# STM32C092 register map
File version: 1.0
CPU: CM0+ r0p0, little endian, MPU, no FPU, 4 interrupt priority bits
Registers are 32-bit, read-write, reset 0x0 unless marked. A register's access mark holds for its fields unless they carry their own. Offsets are from the block's base; [hi:lo] are bit positions; {n}, {i} and the like mark numbered series.

## GPIOA — GPIOA address block description
Base 0x50000000
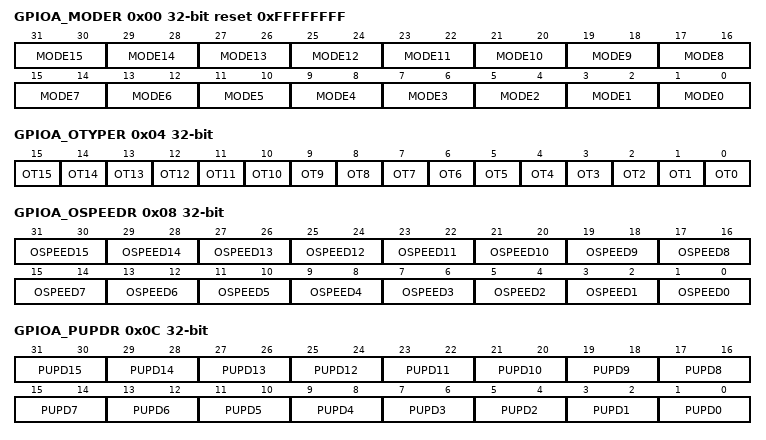
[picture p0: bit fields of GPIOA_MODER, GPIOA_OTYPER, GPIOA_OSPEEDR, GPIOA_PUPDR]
0x00 GPIOA_MODER reset 0xFFFFFFFF — GPIO port mode register
  [all] fields
    0=Input; 1=Output; 2=Alternate function; 3=Analog
  [2n+1:2n] MODE{n} (n=0..15) — Port x configuration for I/O y These bits are written by software to set the I/O to one of four operating modes.
0x04 GPIOA_OTYPER — GPIO port output type register
  [all] fields
    0=Output push-pull (reset state); 1=Output open-drain
  [n] OT{n} (n=0..15) — Port x configuration for I/O y These bits are written by software to configure the I/O output type.
0x08 GPIOA_OSPEEDR — GPIO port output speed register
  [all] fields
    0=Very low speed; 1=Low speed; 2=High speed; 3=Very high speed
  [2n+1:2n] OSPEED{n} (n=0..15) — Port x configuration for I/O y These bits are written by software to configure the I/O output speed. Refer to the device datasheet for the frequency specifications and the power supply and load conditions for each speed.. Note: The FT_c GPIOs cannot be set to high speed.
0x0C GPIOA_PUPDR — GPIO port pull-up/pull-down register
  [all] fields
    0=No pull-up, pull-down; 1=Pull-up; 2=Pull-down
  [2n+1:2n] PUPD{n} (n=0..15) — Port x configuration I/O y These bits are written by software to configure the I/O pull-up or pull-down Note: On the same pin, this pull up/down must not be activated when a pull down/up is set through the PWR_PDCRx/PWR_PUCRx registers.
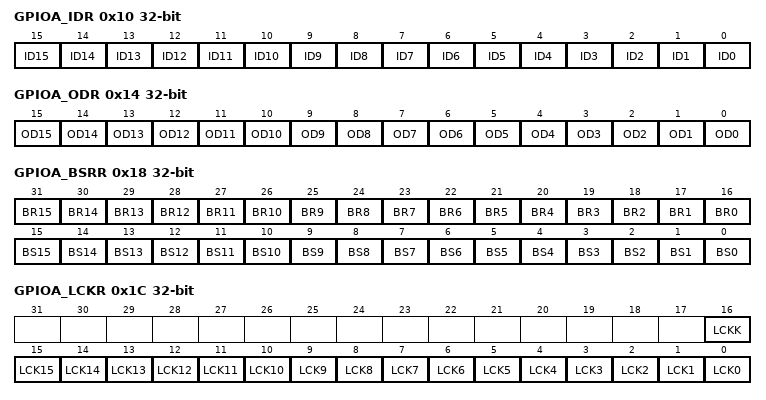
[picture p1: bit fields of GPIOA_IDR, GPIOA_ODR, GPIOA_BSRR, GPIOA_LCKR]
0x10 GPIOA_IDR ro (reset mask 0xFFFF0000) — GPIO port input data register
  [n] ID{n} (n=0..15) — Port x input data I/O y These bits are read-only. They contain the input value of the corresponding I/O port.
0x14 GPIOA_ODR — GPIO port output data register
  [n] OD{n} (n=0..15) — Port output data I/O y These bits can be read and written by software. Note: For atomic bit set/reset, the OD bits can be individually set and/or reset by writing to the GPIOx_BSRR register (x = A, B, C, D, F).
0x18 GPIOA_BSRR wo — GPIO port bit set/reset register
  [n+16] BR{n} (n=0..15) — Port x reset I/O y These bits are write-only. A read operation always returns 0x0000. Note: If both BSx and BRx are set, BSx has priority.
    0=No action on the corresponding ODRx bit; 1=Resets the corresponding ODRx bit
  [n] BS{n} (n=0..15) — Port x set I/O y These bits are write-only. A read operation always returns 0x0000.
    0=No action on the corresponding ODRx bit; 1=Sets the corresponding ODRx bit
0x1C GPIOA_LCKR — GPIO port configuration lock register
  [16] LCKK — Lock key This bit can be read any time. It can only be modified using the lock key write sequence. LOCK key write sequence: WR LCKR[16] = 1 + LCKR[15:0] WR LCKR[16] = 0 + LCKR[15:0] WR LCKR[16] = 1 + LCKR[15:0] RD LCKR RD LCKR[16] = 1 (this read operation is optional but it confirms that the lock is active) Note: During the LOCK key write sequence, the value of LCK[15:0] must not change. Note: Any error in the lock sequence aborts the lock. Note: After the first lock sequence on any bit of the port, any read access on the LCKK bit returns 1 until the next MCU reset or peripheral reset.
    0=Port configuration lock key not active; 1=Port configuration lock key active. The GPIOx_LCKR register is locked until the next MCU reset or peripheral reset.
  [n] LCK{n} (n=0..15) — Port x lock I/O pin y These bits are read/write but can only be written when the LCKK bit is 0.
    0=Port configuration not locked; 1=Port configuration locked
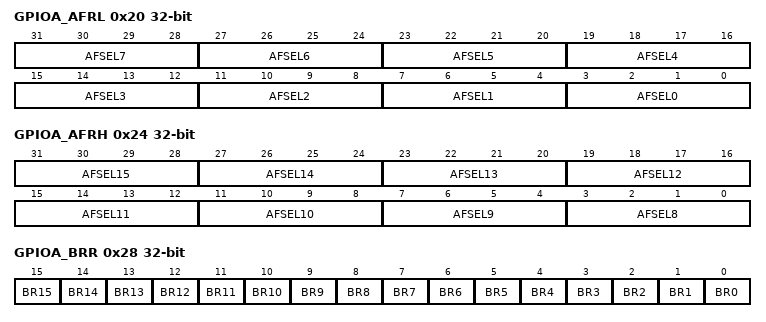
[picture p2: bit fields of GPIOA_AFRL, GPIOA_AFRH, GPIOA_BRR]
0x20 GPIOA_AFRL — GPIO alternate function low register
  [all] fields
    {v}=AF{v} (v=0..15)
  [4n+3:4n] AFSEL{n} (n=0..7) — Alternate function selection for port x pin y These bits are written by software to configure alternate function I/Os
0x24 GPIOA_AFRH — GPIO alternate function high register
  [all] fields
    {v}=AF{v} (v=0..15)
  [4n-29:4n-32] AFSEL{n} (n=8..15) — Alternate function selection for port x, I/O y These bits are written by software to configure alternate function I/Os
0x28 GPIOA_BRR wo — GPIO port bit reset register
  [all] fields
    0=No action on the corresponding ODx bit; 1=Reset the corresponding ODx bit
  [n] BR{n} (n=0..15) — Port x reset I/O y These bits are write-only. A read operation always returns 0x0000.

## GPIOB — GPIOB address block description
Base 0x50000400
Registers as GPIOA (with GPIOA read as GPIOB).

## GPIOC — GPIOC address block description
Base 0x50000800
Registers as GPIOA (with GPIOA read as GPIOC).

## GPIOD — GPIOD address block description
Base 0x50000C00
Registers as GPIOA (with GPIOA read as GPIOD).

## GPIOF — GPIOF address block description
Base 0x50001400
Registers as GPIOA (with GPIOA read as GPIOF).

## Notices in the file
Copyright (c) 2024 STMicroelectronics.
SPDX-License-Identifier: Apache-2.0
Licensed under the Apache License, Version 2.0 (the "License");
you may not use this file except in compliance with the License.
You may obtain a copy of the License at
http://www.apache.org/licenses/LICENSE-2.0
Unless required by applicable law or agreed to in writing, software
distributed under the License is distributed on an "AS IS" BASIS,
WITHOUT WARRANTIES OR CONDITIONS OF ANY KIND, either express or implied.
See the License for the specific language governing permissions and
limitations under the License.
